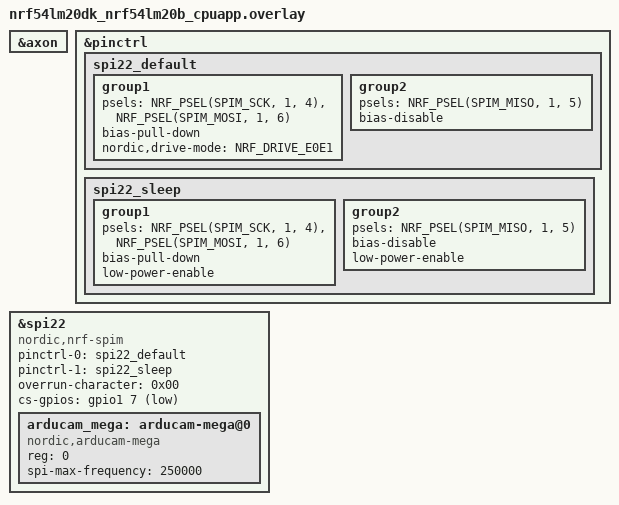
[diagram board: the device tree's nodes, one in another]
/*
 * Copyright (c) 2026 Nordic Semiconductor ASA
 * SPDX-License-Identifier: LicenseRef-Nordic-5-Clause
 */

&axon {
	status = "okay";
};

&pinctrl {
	/* SCK/MOSI: pull-down; stronger drive helps TXS0108E. MISO: no pull (shifter + camera drive). */
	spi22_default: spi22_default {
		group1 {
			psels = <NRF_PSEL(SPIM_SCK, 1, 4)>,
				<NRF_PSEL(SPIM_MOSI, 1, 6)>;
			bias-pull-down;
			nordic,drive-mode = <NRF_DRIVE_E0E1>;
		};
		group2 {
			psels = <NRF_PSEL(SPIM_MISO, 1, 5)>;
			bias-disable;
		};
	};

	spi22_sleep: spi22_sleep {
		group1 {
			psels = <NRF_PSEL(SPIM_SCK, 1, 4)>,
				<NRF_PSEL(SPIM_MOSI, 1, 6)>;
			bias-pull-down;
			low-power-enable;
		};
		group2 {
			psels = <NRF_PSEL(SPIM_MISO, 1, 5)>;
			bias-disable;
			low-power-enable;
		};
	};
};

&spi22 {
	compatible = "nordic,nrf-spim";
	status = "okay";
	pinctrl-0 = <&spi22_default>;
	pinctrl-1 = <&spi22_sleep>;
	pinctrl-names = "default", "sleep";
	overrun-character = <0x00>;
	cs-gpios = <&gpio1 7 GPIO_ACTIVE_LOW>;

	arducam_mega: arducam-mega@0 {
		compatible = "nordic,arducam-mega";
		reg = <0>;
		/* TXS0108E @ 3.3 V: 250 kHz default; nrfx SPIM minimum is 125 kHz (not lower). */
		spi-max-frequency = <250000>;
		status = "okay";
	};
};
